# STM32F205 register map
File version: 1.2
CPU: CM3 r1p1, little endian, no MPU, no FPU, 4 interrupt priority bits
Registers are 32-bit, read-write, reset 0x0 unless marked. A register's access mark holds for its fields unless they carry their own. Offsets are from the block's base; [hi:lo] are bit positions; {n}, {i} and the like mark numbered series; 'fields as' and 'values as' point back to an identical list.

## EXTI — External interrupt/event controller
Base 0x40013C00
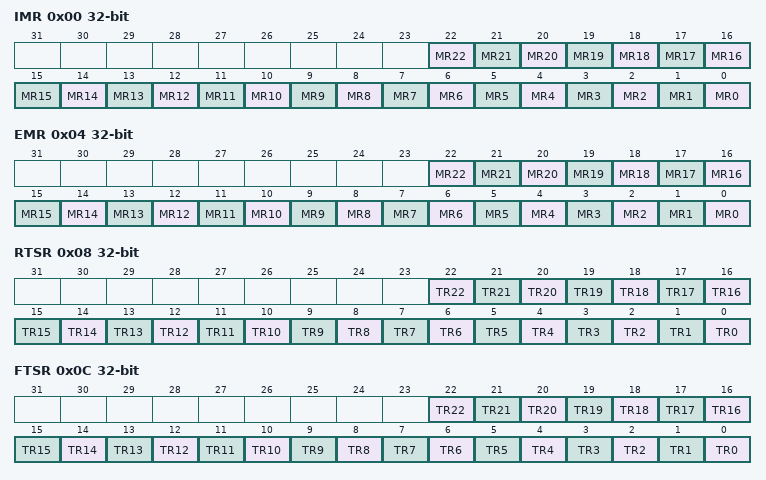
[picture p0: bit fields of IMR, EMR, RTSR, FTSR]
0x00 IMR — Interrupt mask register (EXTI_IMR)
  [n] MR{n} (n=0..22) — Interrupt Mask on line {n}
0x04 EMR — Event mask register (EXTI_EMR)
  [n] MR{n} (n=0..22) — Event Mask on line {n}
0x08 RTSR — Rising Trigger selection register (EXTI_RTSR)
  [n] TR{n} (n=0..22) — Rising trigger event configuration of line {n}
0x0C FTSR — Falling Trigger selection register (EXTI_FTSR)
  [n] TR{n} (n=0..22) — Falling trigger event configuration of line {n}
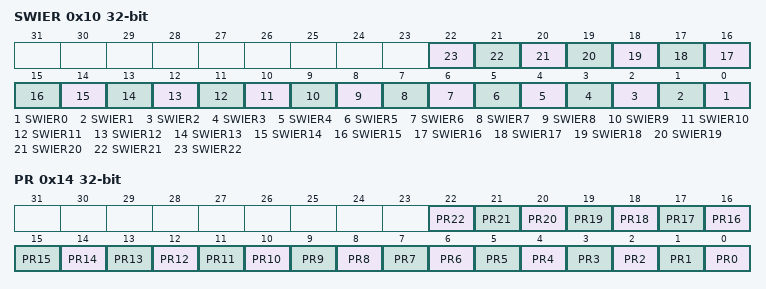
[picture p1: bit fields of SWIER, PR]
0x10 SWIER — Software interrupt event register (EXTI_SWIER)
  [n] SWIER{n} (n=0..22) — Software Interrupt on line {n}
0x14 PR — Pending register (EXTI_PR)
  [n] PR{n} (n=0..22) — Pending bit {n}

## FLASH
Base 0x40023C00
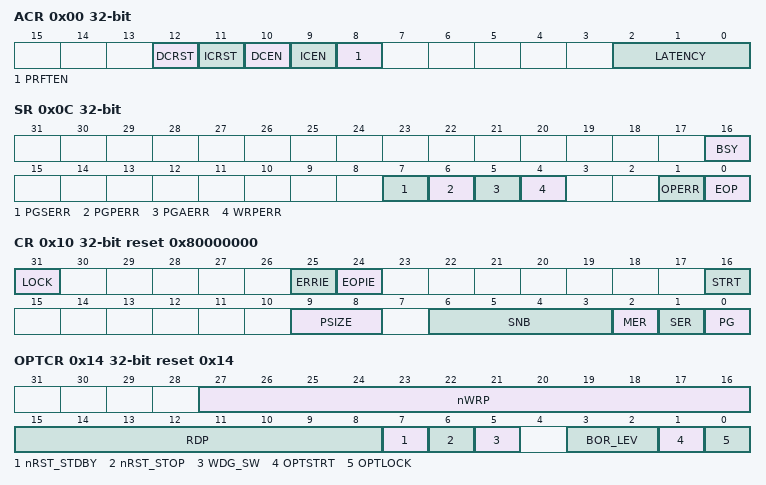
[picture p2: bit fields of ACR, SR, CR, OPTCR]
0x00 ACR access per field — Flash access control register
  [12] DCRST rw — Data cache reset
  [11] ICRST wo — Instruction cache reset
  [10] DCEN rw — Data cache enable
  [9] ICEN rw — Instruction cache enable
  [8] PRFTEN rw — Prefetch enable
  [2:0] LATENCY rw
0x04 KEYR wo — Flash key register
  [31:0] KEY — FPEC key
0x08 OPTKEYR wo — Flash option key register
  [31:0] OPTKEY — Option byte key
0x0C SR access per field — Status register
  [16] BSY ro — Busy
  [7] PGSERR rw — Programming sequence error
  [6] PGPERR rw — Programming parallelism error
  [5] PGAERR rw — Programming alignment error
  [4] WRPERR rw — Write protection error
  [1] OPERR rw — Operation error
  [0] EOP rw — End of operation
0x10 CR reset 0x80000000 — Control register
  [31] LOCK
  [25] ERRIE — Error interrupt enable
  [24] EOPIE — End of operation interrupt enable
  [16] STRT — Start
  [9:8] PSIZE — Program size
  [6:3] SNB — Sector number
  [2] MER — Mass Erase
  [1] SER — Sector Erase
  [0] PG — Programming
0x14 OPTCR reset 0x14 — Flash option control register
  [27:16] nWRP — Not write protect
  [15:8] RDP — Read protect
  [7] nRST_STDBY — nRST_STDBY User option bytes
  [6] nRST_STOP — nRST_STOP User option bytes
  [5] WDG_SW — WDG_SW User option bytes
  [3:2] BOR_LEV — BOR reset Level
  [1] OPTSTRT — Option start
  [0] OPTLOCK — Option lock

## FSMC — Flexible static memory controller
Base 0xA0000000
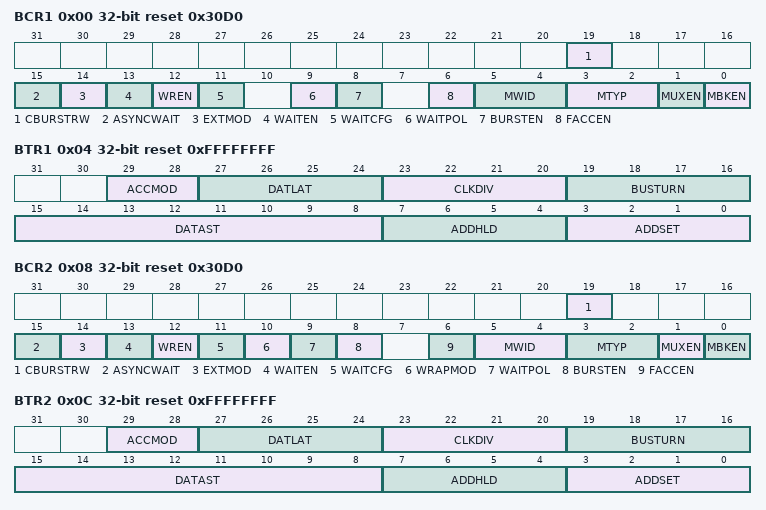
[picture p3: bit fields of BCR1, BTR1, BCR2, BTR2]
0x00 BCR1 reset 0x30D0 — SRAM/NOR-Flash chip-select control register 1
  [19] CBURSTRW, [15] ASYNCWAIT, [14] EXTMOD, [13] WAITEN, [12] WREN, [11] WAITCFG, [9] WAITPOL, [8] BURSTEN, [6] FACCEN, [5:4] MWID, [3:2] MTYP, [1] MUXEN, [0] MBKEN
0x04 BTR1 reset 0xFFFFFFFF — SRAM/NOR-Flash chip-select timing register 1
  [29:28] ACCMOD, [27:24] DATLAT, [23:20] CLKDIV, [19:16] BUSTURN, [15:8] DATAST, [7:4] ADDHLD, [3:0] ADDSET
0x08 BCR2 reset 0x30D0 — SRAM/NOR-Flash chip-select control register 2
  [19] CBURSTRW, [15] ASYNCWAIT, [14] EXTMOD, [13] WAITEN, [12] WREN, [11] WAITCFG, [10] WRAPMOD, [9] WAITPOL, [8] BURSTEN, [6] FACCEN, [5:4] MWID, [3:2] MTYP, [1] MUXEN, [0] MBKEN
0x0C BTR2 reset 0xFFFFFFFF — SRAM/NOR-Flash chip-select timing register 2
  fields as BTR1
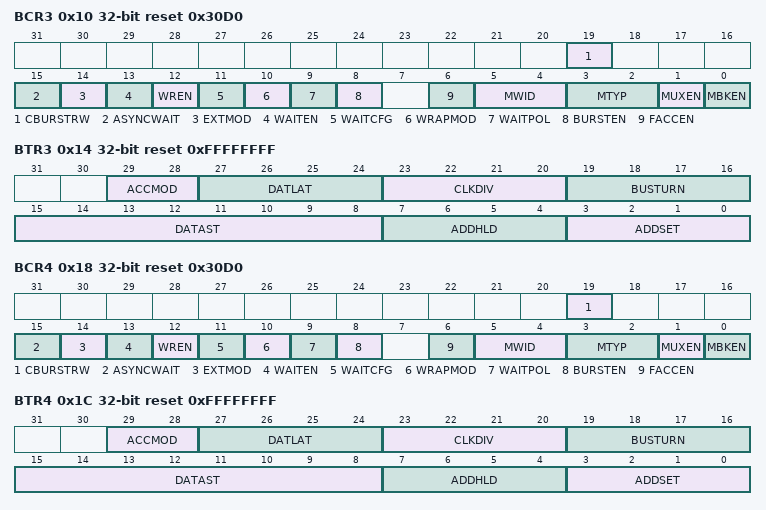
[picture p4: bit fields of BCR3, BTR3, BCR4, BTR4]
0x10 BCR3 reset 0x30D0 — SRAM/NOR-Flash chip-select control register 3
  fields as BCR2
0x14 BTR3 reset 0xFFFFFFFF — SRAM/NOR-Flash chip-select timing register 3
  fields as BTR1
0x18 BCR4 reset 0x30D0 — SRAM/NOR-Flash chip-select control register 4
  fields as BCR2
0x1C BTR4 reset 0xFFFFFFFF — SRAM/NOR-Flash chip-select timing register 4
  fields as BTR1
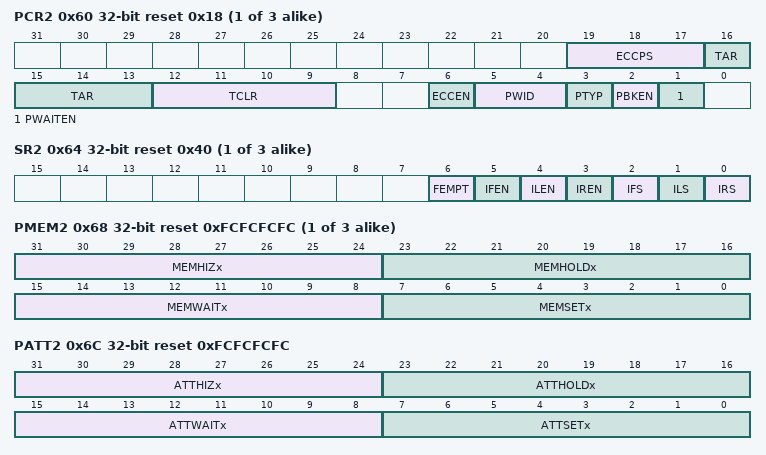
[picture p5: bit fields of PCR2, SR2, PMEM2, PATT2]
{0x20+0x20*i} PCR{i} reset 0x18 (i=2..4) — PC Card/NAND Flash control register {i}
  [19:17] ECCPS, [16:13] TAR, [12:9] TCLR, [6] ECCEN, [5:4] PWID, [3] PTYP, [2] PBKEN, [1] PWAITEN
{0x24+0x20*i} SR{i} access per field reset 0x40 (i=2..4) — FIFO status and interrupt register {i}
  [6] FEMPT ro, [5] IFEN rw, [4] ILEN rw, [3] IREN rw, [2] IFS rw, [1] ILS rw, [0] IRS rw
{0x28+0x20*i} PMEM{i} reset 0xFCFCFCFC (i=2..4) — Common memory space timing register {i}
  [31:24] MEMHIZx, [23:16] MEMHOLDx, [15:8] MEMWAITx, [7:0] MEMSETx
0x6C PATT2 reset 0xFCFCFCFC — Attribute memory space timing register 2
  [31:24] ATTHIZx — Attribute memory x databus HiZ time
  [23:16] ATTHOLDx — Attribute memory x hold time
  [15:8] ATTWAITx — Attribute memory x wait time
  [7:0] ATTSETx — Attribute memory x setup time
0x74 ECCR2 ro — ECC result register 2
  [31:0] ECCx — ECC result
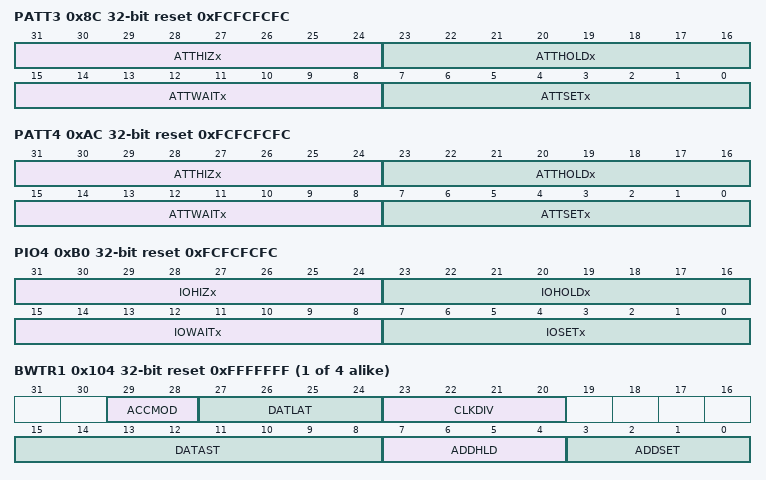
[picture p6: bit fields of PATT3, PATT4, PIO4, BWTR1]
0x8C PATT3 reset 0xFCFCFCFC — Attribute memory space timing register 3
  [31:24] ATTHIZx, [23:16] ATTHOLDx, [15:8] ATTWAITx, [7:0] ATTSETx
0x94 ECCR3 ro — ECC result register 3
  [31:0] ECCx
0xAC PATT4 reset 0xFCFCFCFC — Attribute memory space timing register 4
  [31:24] ATTHIZx, [23:16] ATTHOLDx, [15:8] ATTWAITx, [7:0] ATTSETx
0xB0 PIO4 reset 0xFCFCFCFC — I/O space timing register 4
  [31:24] IOHIZx, [23:16] IOHOLDx, [15:8] IOWAITx, [7:0] IOSETx
{0xFC+8i} BWTR{i} reset 0xFFFFFFF (i=1..4) — SRAM/NOR-Flash write timing registers {i}
  [29:28] ACCMOD, [27:24] DATLAT, [23:20] CLKDIV, [15:8] DATAST, [7:4] ADDHLD, [3:0] ADDSET

## Notices in the file
Copyright (c) 2024 STMicroelectronics.
SPDX-License-Identifier: Apache-2.0
Licensed under the Apache License, Version 2.0 (the "License");
you may not use this file except in compliance with the License.
You may obtain a copy of the License at
http://www.apache.org/licenses/LICENSE-2.0
Unless required by applicable law or agreed to in writing, software
distributed under the License is distributed on an "AS IS" BASIS,
WITHOUT WARRANTIES OR CONDITIONS OF ANY KIND, either express or implied.
See the License for the specific language governing permissions and
limitations under the License.
